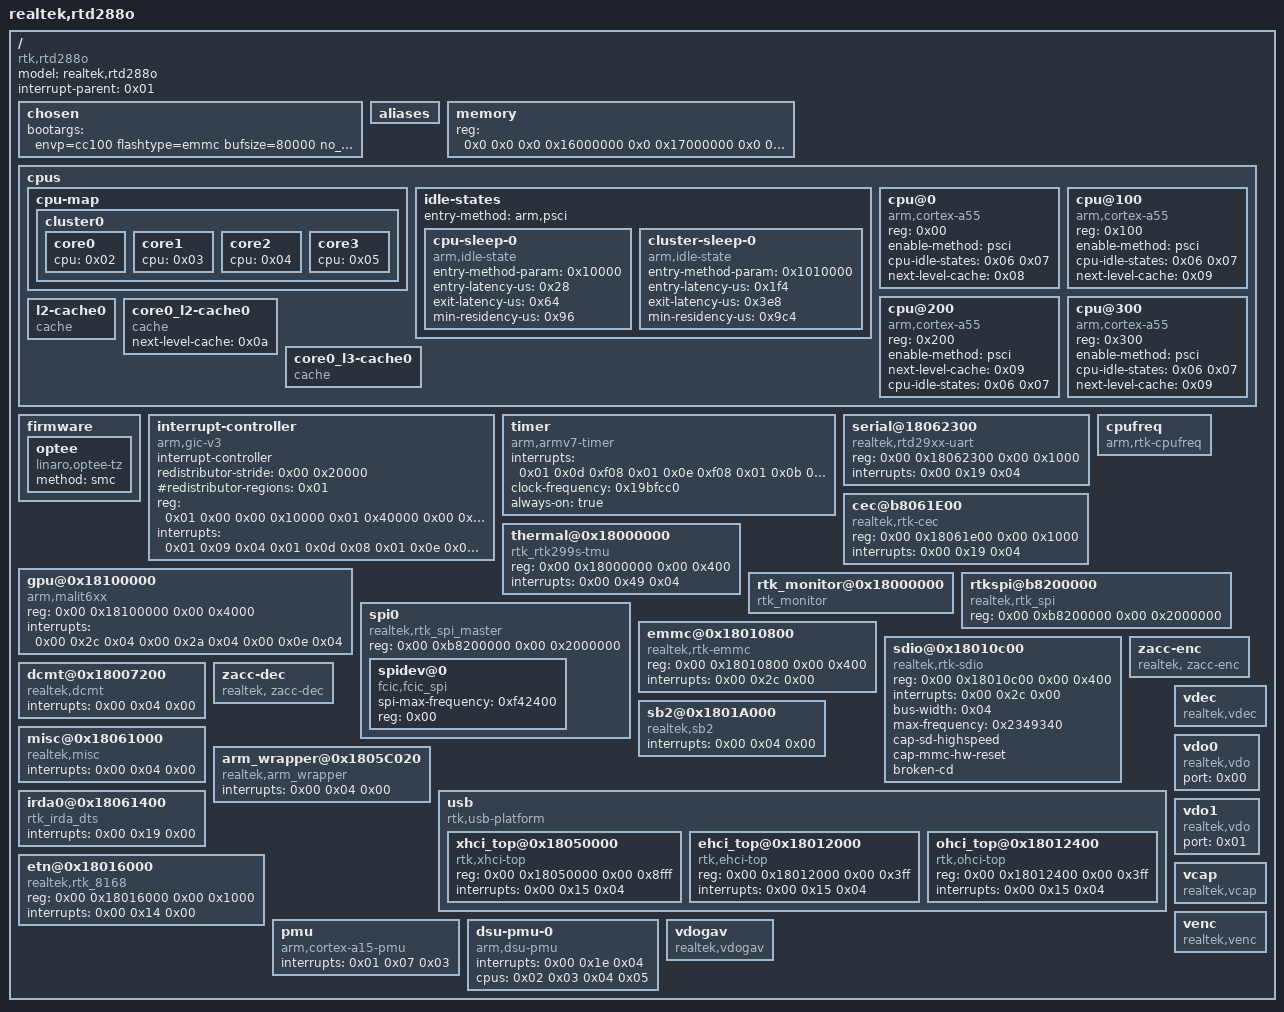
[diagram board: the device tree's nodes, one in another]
/dts-v1/;
/memreserve/ 0x3400000 0x400000;
/memreserve/ 0x1ae00000 0x400000;

/memreserve/ 0x0000000000000000 0x0000000000108000;

/ {
	#address-cells = <0x02>;
	#size-cells = <0x02>;
	model = "realtek,rtd288o";
	compatible = "rtk,rtd288o";
	interrupt-parent = <0x01>;

	chosen {
		bootargs = "envp=cc100 flashtype=emmc bufsize=80000 no_console_suspend bcas=off emmc_clock=200 eBackLight=direct eLEDBarType=6 bLocalDimming=0 eModelInchType=43 eModelToolType=UN71 eModelModuleType=BOE pwm_mode=1 ethaddr=A8:23:FE:FA:1C:A8 rtdlog=3000 devtmpfs.mount=1 modelopt=21003004 hwopt=203200001003002000 ToolOpt=203114:16406:35584:65:60351524:273731337 debugMode=5 modelName=43UN71006LB countryGrp=22 sver=6.00.131 bver=6.00.131 chip=K6LPA0 extmod=LGTV emmc_size=0x1d2000000 console=ttyS0,9600 earlyprintk loglevel=8 ignore_loglevel root=/dev/ram0 ro rdinit=/init nr_cpus=1 maxcpus=1 panic=5 initcall_debug initcall_blacklist=rtk_platform_arm_wrapper_driver_init,rtk_sb2_driver_init,sb2_extra_module_init,GDMA_init_module";
	};

	aliases {
	};

	memory {
		device_type = "memory";
		reg = <0x0 0x0 0x0 0x16000000 0x0 0x17000000 0x0 0x1000000 0x0 0x18200000 0x0 0x2300000 0x0 0x1ae00000 0x0 0x400000 0x0 0x1c600000 0x0 0x43a00000>;
	};

	cpus {
		#address-cells = <0x01>;
		#size-cells = <0x00>;

		cpu-map {

			cluster0 {
				#cooling-cells = <0x02>;

				core0 {
					cpu = <0x02>;
				};

				core1 {
					cpu = <0x03>;
				};

				core2 {
					cpu = <0x04>;
				};

				core3 {
					cpu = <0x05>;
				};
			};
		};

		idle-states {
			entry-method = "arm,psci";

			cpu-sleep-0 {
				compatible = "arm,idle-state";
				entry-method-param = <0x10000>;
				entry-latency-us = <0x28>;
				exit-latency-us = <0x64>;
				min-residency-us = <0x96>;
				linux,phandle = <0x06>;
				phandle = <0x06>;
			};

			cluster-sleep-0 {
				compatible = "arm,idle-state";
				entry-method-param = <0x1010000>;
				entry-latency-us = <0x1f4>;
				exit-latency-us = <0x3e8>;
				min-residency-us = <0x9c4>;
				linux,phandle = <0x07>;
				phandle = <0x07>;
			};
		};

		cpu@0 {
			compatible = "arm,cortex-a55", "arm,armv8";
			reg = <0x00>;
			device_type = "cpu";
			enable-method = "psci";
			cpu-idle-states = <0x06 0x07>;
			next-level-cache = <0x08>;
			clock-names = "vlittle";
			linux,phandle = <0x02>;
			phandle = <0x02>;
		};

		cpu@100 {
			compatible = "arm,cortex-a55", "arm,armv8";
			reg = <0x100>;
			device_type = "cpu";
			enable-method = "psci";
			cpu-idle-states = <0x06 0x07>;
			next-level-cache = <0x09>;
			clock-names = "vlittle";
			linux,phandle = <0x03>;
			phandle = <0x03>;
		};

		cpu@200 {
			compatible = "arm,cortex-a55", "arm,armv8";
			reg = <0x200>;
			device_type = "cpu";
			enable-method = "psci";
			next-level-cache = <0x09>;
			cpu-idle-states = <0x06 0x07>;
			clock-names = "vlittle";
			linux,phandle = <0x04>;
			phandle = <0x04>;
		};

		cpu@300 {
			compatible = "arm,cortex-a55", "arm,armv8";
			reg = <0x300>;
			device_type = "cpu";
			enable-method = "psci";
			cpu-idle-states = <0x06 0x07>;
			next-level-cache = <0x09>;
			clock-names = "vlittle";
			linux,phandle = <0x05>;
			phandle = <0x05>;
		};

		l2-cache0 {
			compatible = "cache";
			linux,phandle = <0x09>;
			phandle = <0x09>;
		};

		core0_l2-cache0 {
			compatible = "cache";
			next-level-cache = <0x0a>;
			linux,phandle = <0x08>;
			phandle = <0x08>;
		};

		core0_l3-cache0 {
			compatible = "cache";
			linux,phandle = <0x0a>;
			phandle = <0x0a>;
		};
	};

	firmware {

		optee {
			compatible = "linaro,optee-tz";
			method = "smc";
		};
	};

	interrupt-controller {
		compatible = "arm,gic-v3";
		#interrupt-cells = <0x03>;
		#address-cells = <0x02>;
		#size-cells = <0x02>;
		interrupt-controller;
		redistributor-stride = <0x00 0x20000>;
		#redistributor-regions = <0x01>;
		reg = <0x01 0x00 0x00 0x10000 0x01 0x40000 0x00 0x200000>;
		interrupts = <0x01 0x09 0x04 0x01 0x0d 0x08 0x01 0x0e 0x08 0x01 0x0b 0x08 0x01 0x0a 0x08 0x00 0x00 0x04 0x00 0x01 0x04 0x00 0x02 0x04 0x00 0x03 0x04 0x00 0x04 0x04 0x00 0x05 0x04 0x00 0x06 0x04 0x00 0x07 0x04 0x00 0x08 0x04 0x00 0x09 0x04 0x00 0x0a 0x04 0x00 0x0b 0x04 0x00 0x0c 0x04 0x00 0x0d 0x04 0x00 0x0e 0x04 0x00 0x0f 0x04 0x00 0x10 0x04 0x00 0x11 0x04 0x00 0x12 0x04 0x00 0x13 0x04 0x00 0x14 0x04 0x00 0x15 0x04 0x00 0x16 0x04 0x00 0x17 0x04 0x00 0x18 0x04 0x00 0x19 0x04 0x00 0x1a 0x04 0x00 0x1b 0x04 0x00 0x1c 0x04 0x00 0x1d 0x04 0x00 0x1e 0x04 0x00 0x1f 0x04 0x00 0x20 0x04 0x00 0x21 0x04 0x00 0x22 0x04 0x00 0x23 0x04 0x00 0x24 0x04 0x00 0x25 0x04 0x00 0x26 0x04 0x00 0x27 0x04 0x00 0x28 0x04 0x00 0x29 0x04 0x00 0x2a 0x04 0x00 0x2b 0x04 0x00 0x2c 0x04 0x00 0x2d 0x04 0x00 0x2e 0x04 0x00 0x2f 0x04 0x00 0x30 0x04 0x00 0x31 0x04 0x00 0x32 0x04 0x00 0x33 0x04 0x00 0x34 0x04 0x00 0x35 0x04 0x00 0x36 0x04 0x00 0x37 0x04 0x00 0x38 0x04 0x00 0x39 0x04 0x00 0x3a 0x04 0x00 0x3b 0x04 0x00 0x3c 0x04 0x00 0x3d 0x04 0x00 0x3e 0x04 0x00 0x3f 0x04 0x00 0x40 0x04 0x00 0x41 0x04 0x00 0x42 0x04 0x00 0x43 0x04 0x00 0x44 0x04 0x00 0x45 0x04 0x00 0x46 0x04 0x00 0x47 0x04 0x00 0x48 0x04 0x00 0x49 0x04 0x00 0x4a 0x04 0x00 0x4b 0x04 0x00 0x4c 0x04 0x00 0x4d 0x04 0x00 0x4e 0x04 0x00 0x4f 0x04>;
		linux,phandle = <0x01>;
		phandle = <0x01>;
	};

	timer {
		compatible = "arm,armv7-timer";
		interrupts = <0x01 0x0d 0xf08 0x01 0x0e 0xf08 0x01 0x0b 0xf08 0x01 0x0a 0xf08>;
		clock-frequency = <0x19bfcc0>;
		always-on = "true";
	};

	serial@18062300 {
		#address-cells = <0x02>;
		#size-cells = <0x02>;
		compatible = "realtek,rtd29xx-uart";
		reg = <0x00 0x18062300 0x00 0x1000>;
		interrupts = <0x00 0x19 0x04>;
	};

	cec@b8061E00 {
		#address-cells = <0x02>;
		#size-cells = <0x02>;
		compatible = "realtek,rtk-cec";
		reg = <0x00 0x18061e00 0x00 0x1000>;
		interrupts = <0x00 0x19 0x04>;
	};

	gpu@0x18100000 {
		compatible = "arm,malit6xx", "arm,mali-midgard";
		reg = <0x00 0x18100000 0x00 0x4000>;
		interrupts = <0x00 0x2c 0x04 0x00 0x2a 0x04 0x00 0x0e 0x04>;
		interrupt-names = "JOB", "MMU", "GPU";
		clock-names = "clk_mali";
	};

	cpufreq {
		compatible = "arm,rtk-cpufreq";
	};

	thermal@0x18000000 {
		#address-cells = <0x02>;
		#size-cells = <0x02>;
		compatible = "rtk_rtk299s-tmu";
		reg = <0x00 0x18000000 0x00 0x400>;
		interrupts = <0x00 0x49 0x04>;
		status = "okay";
	};

	rtk_monitor@0x18000000 {
		compatible = "rtk_monitor";
		status = "okay";
	};

	rtkspi@b8200000 {
		#address-cells = <0x02>;
		#size-cells = <0x02>;
		compatible = "realtek,rtk_spi";
		reg = <0x00 0xb8200000 0x00 0x2000000>;
	};

	spi0 {
		compatible = "realtek,rtk_spi_master";
		reg = <0x00 0xb8200000 0x00 0x2000000>;
		status = "okay";
		#address-cells = <0x02>;
		#size-cells = <0x02>;

		spidev@0 {
			compatible = "fcic,fcic_spi";
			spi-max-frequency = <0xf42400>;
			reg = <0x00>;
		};
	};

	emmc@0x18010800 {
		#address-cells = <0x01>;
		#size-cells = <0x01>;
		compatible = "realtek,rtk-emmc";
		reg = <0x00 0x18010800 0x00 0x400>;
		interrupts = <0x00 0x2c 0x00>;
	};

	sdio@0x18010c00 {
		compatible = "realtek,rtk-sdio";
		reg = <0x00 0x18010c00 0x00 0x400>;
		interrupts = <0x00 0x2c 0x00>;
		bus-width = <0x04>;
		max-frequency = <0x2349340>;
		cap-sd-highspeed;
		cap-mmc-hw-reset;
		broken-cd;
	};

	dcmt@0x18007200 {
		compatible = "realtek,dcmt";
		interrupts = <0x00 0x04 0x00>;
	};

	sb2@0x1801A000 {
		compatible = "realtek,sb2";
		interrupts = <0x00 0x04 0x00>;
	};

	zacc-enc {
		compatible = "realtek, zacc-enc";
	};

	zacc-dec {
		compatible = "realtek, zacc-dec";
	};

	misc@0x18061000 {
		compatible = "realtek,misc";
		interrupts = <0x00 0x04 0x00>;
	};

	arm_wrapper@0x1805C020 {
		compatible = "realtek,arm_wrapper";
		interrupts = <0x00 0x04 0x00>;
	};

	usb {
		compatible = "rtk,usb-platform";
		ranges;

		xhci_top@0x18050000 {
			compatible = "rtk,xhci-top";
			reg = <0x00 0x18050000 0x00 0x8fff>;
			interrupts = <0x00 0x15 0x04>;
		};

		ehci_top@0x18012000 {
			compatible = "rtk,ehci-top";
			reg = <0x00 0x18012000 0x00 0x3ff>;
			interrupts = <0x00 0x15 0x04>;
		};

		ohci_top@0x18012400 {
			compatible = "rtk,ohci-top";
			reg = <0x00 0x18012400 0x00 0x3ff>;
			interrupts = <0x00 0x15 0x04>;
		};
	};

	irda0@0x18061400 {
		compatible = "rtk_irda_dts";
		interrupts = <0x00 0x19 0x00>;
	};

	etn@0x18016000 {
		compatible = "realtek,rtk_8168";
		reg = <0x00 0x18016000 0x00 0x1000>;
		interrupts = <0x00 0x14 0x00>;
	};

	pmu {
		compatible = "arm,cortex-a15-pmu";
		interrupts = <0x01 0x07 0x03>;
	};

	dsu-pmu-0 {
		compatible = "arm,dsu-pmu";
		interrupts = <0x00 0x1e 0x04>;
		cpus = <0x02 0x03 0x04 0x05>;
	};

	vdec {
		compatible = "realtek,vdec";
	};

	vdo0 {
		compatible = "realtek,vdo";
		port = <0x00>;
	};

	vdo1 {
		compatible = "realtek,vdo";
		port = <0x01>;
	};

	vcap {
		compatible = "realtek,vcap";
	};

	venc {
		compatible = "realtek,venc";
	};

	vdogav {
		compatible = "realtek,vdogav";
	};
};
